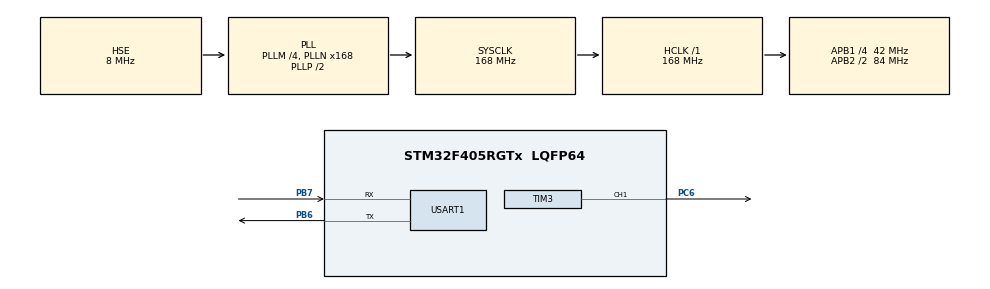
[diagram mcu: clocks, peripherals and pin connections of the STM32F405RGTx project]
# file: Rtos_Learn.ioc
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Dma.Request0=TIM3_CH1/TRIG
Dma.Request1=USART1_TX
Dma.Request2=USART1_RX
Dma.TIM3_CH1/TRIG.0.Direction=DMA_MEMORY_TO_PERIPH
Dma.TIM3_CH1/TRIG.0.FIFOMode=DMA_FIFOMODE_DISABLE
Dma.TIM3_CH1/TRIG.0.Instance=DMA1_Stream4
Dma.TIM3_CH1/TRIG.0.MemDataAlignment=DMA_MDATAALIGN_HALFWORD
Dma.TIM3_CH1/TRIG.0.MemInc=DMA_MINC_ENABLE
Dma.TIM3_CH1/TRIG.0.Mode=DMA_NORMAL
Dma.TIM3_CH1/TRIG.0.PeriphDataAlignment=DMA_PDATAALIGN_HALFWORD
Dma.TIM3_CH1/TRIG.0.PeriphInc=DMA_PINC_DISABLE
Dma.TIM3_CH1/TRIG.0.Priority=DMA_PRIORITY_HIGH
Dma.USART1_RX.2.Direction=DMA_PERIPH_TO_MEMORY
Dma.USART1_RX.2.FIFOMode=DMA_FIFOMODE_DISABLE
Dma.USART1_RX.2.Instance=DMA2_Stream2
Dma.USART1_RX.2.MemDataAlignment=DMA_MDATAALIGN_BYTE
Dma.USART1_RX.2.MemInc=DMA_MINC_ENABLE
Dma.USART1_RX.2.Mode=DMA_NORMAL
Dma.USART1_RX.2.PeriphDataAlignment=DMA_PDATAALIGN_BYTE
Dma.USART1_RX.2.PeriphInc=DMA_PINC_DISABLE
Dma.USART1_RX.2.Priority=DMA_PRIORITY_LOW
Dma.USART1_TX.1.Direction=DMA_MEMORY_TO_PERIPH
Dma.USART1_TX.1.FIFOMode=DMA_FIFOMODE_DISABLE
Dma.USART1_TX.1.Instance=DMA2_Stream7
Dma.USART1_TX.1.MemDataAlignment=DMA_MDATAALIGN_BYTE
Dma.USART1_TX.1.MemInc=DMA_MINC_ENABLE
Dma.USART1_TX.1.Mode=DMA_NORMAL
Dma.USART1_TX.1.PeriphDataAlignment=DMA_PDATAALIGN_BYTE
Dma.USART1_TX.1.PeriphInc=DMA_PINC_DISABLE
Dma.USART1_TX.1.Priority=DMA_PRIORITY_LOW
Mcu.Family=STM32F4
Mcu.Name=STM32F405RGTx
Mcu.Package=LQFP64
NVIC.DMA1_Stream4_IRQn=true\:0\:0\:false\:false\:true\:false\:true\:true
NVIC.DMA2_Stream2_IRQn=true\:0\:0\:false\:false\:true\:false\:true\:true
NVIC.DMA2_Stream7_IRQn=true\:0\:0\:false\:false\:true\:false\:true\:true
NVIC.PriorityGroup=NVIC_PRIORITYGROUP_4
NVIC.TIM1_UP_TIM10_IRQn=true\:15\:0\:false\:false\:true\:false\:true\:true
NVIC.TimeBase=TIM1_UP_TIM10_IRQn
NVIC.TimeBaseIP=TIM1
NVIC.USART1_IRQn=true\:0\:0\:false\:false\:true\:true\:true\:true
PB6.Mode=Asynchronous
PB6.Signal=USART1_TX
PB7.Mode=Asynchronous
PB7.Signal=USART1_RX
PC6.GPIO_Speed=GPIO_SPEED_FREQ_VERY_HIGH
PC6.Signal=S_TIM3_CH1
PH0-OSC_IN.Mode=HSE-External-Oscillator
PH0-OSC_IN.Signal=RCC_OSC_IN
PH1-OSC_OUT.Mode=HSE-External-Oscillator
PH1-OSC_OUT.Signal=RCC_OSC_OUT
ProjectManager.HeapSize=0x200
ProjectManager.StackSize=0x400
ProjectManager.TargetToolchain=CMake
RCC.48MHZClocksFreq_Value=84000000
RCC.AHBFreq_Value=168000000
RCC.APB1CLKDivider=RCC_HCLK_DIV4
RCC.APB1Freq_Value=42000000
RCC.APB1TimFreq_Value=84000000
RCC.APB2CLKDivider=RCC_HCLK_DIV2
RCC.APB2Freq_Value=84000000
RCC.APB2TimFreq_Value=168000000
RCC.CortexFreq_Value=168000000
RCC.HCLKFreq_Value=168000000
RCC.HSE_VALUE=8000000
RCC.HSI_VALUE=16000000
RCC.LSE_VALUE=32768
RCC.PLLM=4
RCC.PLLN=168
RCC.PLLSourceVirtual=RCC_PLLSOURCE_HSE
RCC.SYSCLKFreq_VALUE=168000000
RCC.SYSCLKSource=RCC_SYSCLKSOURCE_PLLCLK
RCC.VCOOutputFreq_Value=336000000
SH.S_TIM3_CH1.0=TIM3_CH1,PWM Generation1 CH1
TIM3.Channel-PWM\ Generation1\ CH1=TIM_CHANNEL_1
TIM3.Period=105 - 1
USART1.VirtualMode=VM_ASYNC
VP_SYS_VS_tim1.Mode=TIM1
VP_TIM3_VS_ClockSourceINT.Mode=Internal
board=custom

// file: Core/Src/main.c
/* USER CODE BEGIN Header */
/**
  ******************************************************************************
  * @file           : main.c
  * @brief          : Main program body
  ******************************************************************************
  * @attention
  *
  * Copyright (c) 2026 STMicroelectronics.
  * All rights reserved.
  *
  * This software is licensed under terms that can be found in the LICENSE file
  * in the root directory of this software component.
  * If no LICENSE file comes with this software, it is provided AS-IS.
  *
  ******************************************************************************
  */
/* USER CODE END Header */
#include "main.h"
#include "dma.h"
#include "tim.h"
#include "usart.h"
#include "gpio.h"

/* USER CODE BEGIN Includes */
#include "ws2812.h"
#include "semaphore.h"
#include "schedule.h"
#include "queue.h"
#include "VOFA.h"
/* USER CODE END Includes */

/* USER CODE BEGIN PD */
#define LED_NUM 1
/* USER CODE END PD */

/* USER CODE BEGIN PV */
WS2812 ws2812;
static WS2812_Color ws2812_pixels[LED_NUM];
static uint16_t ws2812_dma_buffer[WS2812_DMA_BUFFER_LENGTH(LED_NUM)];

TaskHandle_t task1_handle = NULL;
TaskHandle_t task2_handle = NULL;
Semaphore_t *testSemphore = NULL;
/* USER CODE END PV */

void SystemClock_Config(void);
/* USER CODE BEGIN PFP */
void Task1(void *parameters) {
    Printf("Task 1 is running\n");
    while (1) {
        uint8_t res = SemaphoreTake(testSemphore, 100);
        if (res) {
            Printf("receive semphore\n");
        } else {
            Printf("no\n");
        }

    }
}
void Task2(void *parameters) {

    Printf("Task 2 running\n");
    while (1) {
        SemaphoreRelease(testSemphore);
        TaskDelay(1000);
    }
}

void App() {
    TaskCreate(
        Task1,
        128,
        NULL,
        1,
        &task1_handle
    );
    TaskCreate(
        Task2,
        128,
        NULL,
        8,
        &task2_handle
    );

    testSemphore = SemaphoreCreate(1);
}
/* USER CODE END PFP */

int main(void)
{

  /* MCU Configuration--------------------------------------------------------*/

  /* Reset of all peripherals, Initializes the Flash interface and the Systick. */
  HAL_Init();

  /* Configure the system clock */
  SystemClock_Config();

  /* Initialize all configured peripherals */
  MX_GPIO_Init();
  MX_DMA_Init();
  MX_TIM3_Init();
  MX_USART1_UART_Init();
  /* USER CODE BEGIN 2 */

  WS2812_Create(&ws2812);
  ws2812.Init(&ws2812,
              &htim3,
              TIM_CHANNEL_1,
              ws2812_pixels,
              LED_NUM,
              ws2812_dma_buffer,
              WS2812_DMA_BUFFER_LENGTH(LED_NUM));
  ws2812.SetBrightness(&ws2812, 80);  // 亮度 0~255

  VOFA_Init();
  SchedulerInit();
  App();
  SchedulerStart();

  /* USER CODE END 2 */

  /* Infinite loop */
  while (1)
  {

  }
}

void SystemClock_Config(void)
{
  RCC_OscInitTypeDef RCC_OscInitStruct = {0};
  RCC_ClkInitTypeDef RCC_ClkInitStruct = {0};

  /** Configure the main internal regulator output voltage
  */
  __HAL_RCC_PWR_CLK_ENABLE();
  __HAL_PWR_VOLTAGESCALING_CONFIG(PWR_REGULATOR_VOLTAGE_SCALE1);

  /** Initializes the RCC Oscillators according to the specified parameters
  * in the RCC_OscInitTypeDef structure.
  */
  RCC_OscInitStruct.OscillatorType = RCC_OSCILLATORTYPE_HSE;
  RCC_OscInitStruct.HSEState = RCC_HSE_ON;
  RCC_OscInitStruct.PLL.PLLState = RCC_PLL_ON;
  RCC_OscInitStruct.PLL.PLLSource = RCC_PLLSOURCE_HSE;
  RCC_OscInitStruct.PLL.PLLM = 4;
  RCC_OscInitStruct.PLL.PLLN = 168;
  RCC_OscInitStruct.PLL.PLLP = RCC_PLLP_DIV2;
  RCC_OscInitStruct.PLL.PLLQ = 4;
  if (HAL_RCC_OscConfig(&RCC_OscInitStruct) != HAL_OK)
  {
    Error_Handler();
  }

  /** Initializes the CPU, AHB and APB buses clocks
  */
  RCC_ClkInitStruct.ClockType = RCC_CLOCKTYPE_HCLK|RCC_CLOCKTYPE_SYSCLK
                              |RCC_CLOCKTYPE_PCLK1|RCC_CLOCKTYPE_PCLK2;
  RCC_ClkInitStruct.SYSCLKSource = RCC_SYSCLKSOURCE_PLLCLK;
  RCC_ClkInitStruct.AHBCLKDivider = RCC_SYSCLK_DIV1;
  RCC_ClkInitStruct.APB1CLKDivider = RCC_HCLK_DIV4;
  RCC_ClkInitStruct.APB2CLKDivider = RCC_HCLK_DIV2;

  if (HAL_RCC_ClockConfig(&RCC_ClkInitStruct, FLASH_LATENCY_5) != HAL_OK)
  {
    Error_Handler();
  }
}

void HAL_TIM_PeriodElapsedCallback(TIM_HandleTypeDef *htim)
{
  if (htim->Instance == TIM1)
  {
    HAL_IncTick();
  }
}

void Error_Handler(void)
{
  __disable_irq();
  while (1)
  {
  }
}
